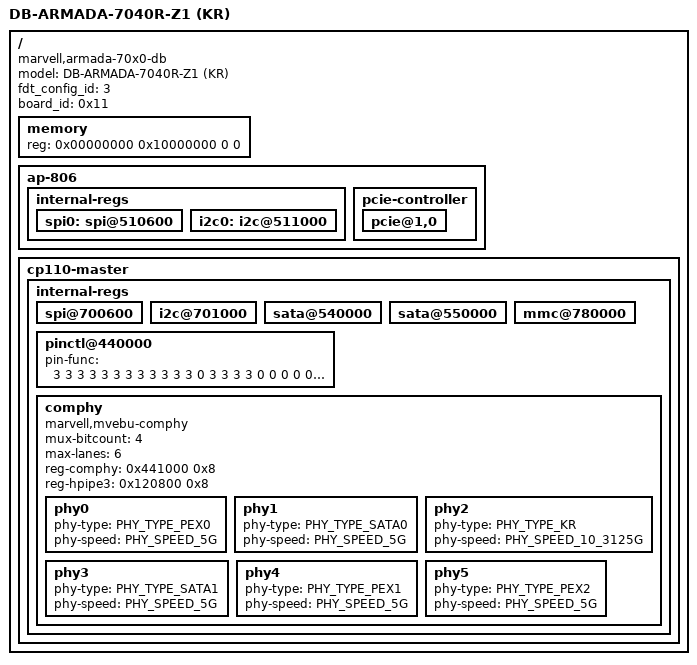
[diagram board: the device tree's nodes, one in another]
/*
 * ***************************************************************************
 * Copyright (C) 2015 Marvell International Ltd.
 * ***************************************************************************
 * This program is free software: you can redistribute it and/or modify it
 * under the terms of the GNU General Public License as published by the Free
 * Software Foundation, either version 2 of the License, or any later version.
 *
 * This program is distributed in the hope that it will be useful,
 * but WITHOUT ANY WARRANTY; without even the implied warranty of
 * MERCHANTABILITY or FITNESS FOR A PARTICULAR PURPOSE.  See the
 * GNU General Public License for more details.
 *
 * You should have received a copy of the GNU General Public License
 * along with this program.  If not, see <http://www.gnu.org/licenses/>.
 * ***************************************************************************
 */

/dts-v1/;

#include "armada-70x0.dtsi" /* include SoC device tree */
#include "armada-70x0-dev-info.dtsi" /* include Marvell specific info (S@R, MPP cmd) */

/ {
	model = "DB-ARMADA-7040R-Z1 (KR)";
	compatible = "marvell,armada-70x0-db", "marvell,armada-70x0";
	fdt_config_id = <3>;
	board_id = <0x11>;

	memory {
		device_type = "memory";
		reg = <0x00000000 0x10000000 0 0>; /* 256 MB */
	};
	ap-806 {
		internal-regs {
			spi0: spi@510600 {
				status = "okay";
			};
			i2c0: i2c@511000 {
				status = "okay";
			};
		};

		pcie-controller {
			pcie@1,0 {
				status = "okay";
			};
		};
	};
	cp110-master {
		internal-regs {
			spi@700600 {
				status = "okay";
			};
			i2c@701000 {
				status = "okay";
			};
			sata@540000 {
				status = "okay";
			};
			sata@550000 {
				status = "okay";
			};
			mmc@780000 {
				status = "okay";
			};

			pinctl@440000 {
					/* MPP Bus:
					   RGMII0 [0-12]
					   SPI    [13-16]
					   SATA1  [28]
					   UART0  [29-30]
					   SMI	  [32,34]
					   SATA0  [36]
					   I2C	  [37-38]
					   UART1  [40-41]
					   XSMI	  [42-43]
					   RGMII1 [44-55]
					   SD	  [56-62]
					*/
					/*   0   1   2   3   4   5   6   7   8   9 */
				pin-func = < 3   3   3   3   3   3   3   3   3   3
					     3   3   0   3   3   3   3   0   0   0
					     0   0   0   0   0   0   0   0   9   0xA
					     0xA 0   7   0   7   0   6   2   2   0
					     7   7   8   8   1   1   1   1   1   1
					     1 	 1   1   1   1   1   0xE 0xE 0xE 0xE
					     0xE 0xE 0xE 0>;
			};

			comphy {
				compatible = "marvell,mvebu-comphy", "marvell,comphy-cp110";
				mux-bitcount = <4>;
				max-lanes = <6>;
				reg-comphy = <0x441000 0x8>;
				reg-hpipe3 = <0x120800 0x8>;
				/* Serdes Configuration:
					Lane 0: PEX0x1
					Lane 1: SATA0
					Lane 2: 10GKR
					Lane 3: SATA1
					Lane 4: PEX1x1
					Lane 5: PEX2x1
				*/
				phy0 {
					phy-type = <PHY_TYPE_PEX0>;
					phy-speed = <PHY_SPEED_5G>;
				};
				phy1 {
					phy-type = <PHY_TYPE_SATA0>;
					phy-speed = <PHY_SPEED_5G>;
				};
				phy2 {
					phy-type = <PHY_TYPE_KR>;
					phy-speed = <PHY_SPEED_10_3125G>;
				};
				phy3 {
					phy-type = <PHY_TYPE_SATA1>;
					phy-speed = <PHY_SPEED_5G>;
				};
				phy4 {
					phy-type = <PHY_TYPE_PEX1>;
					phy-speed = <PHY_SPEED_5G>;
				};
				phy5 {
					phy-type = <PHY_TYPE_PEX2>;
					phy-speed = <PHY_SPEED_5G>;
				};
			};
		};
	};
};
